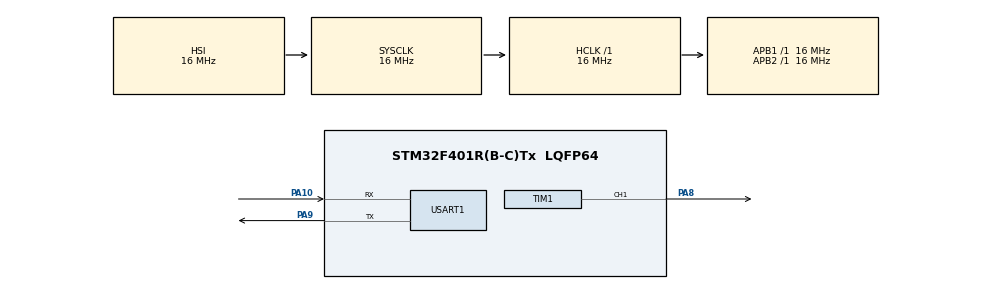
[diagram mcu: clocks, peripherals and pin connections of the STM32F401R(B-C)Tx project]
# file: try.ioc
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Mcu.Family=STM32F4
Mcu.Name=STM32F401R(B-C)Tx
Mcu.Package=LQFP64
NVIC.PriorityGroup=NVIC_PRIORITYGROUP_4
PA10.Mode=Asynchronous
PA10.Signal=USART1_RX
PA13.Mode=Serial_Wire
PA13.Signal=SYS_JTMS-SWDIO
PA14.Mode=Serial_Wire
PA14.Signal=SYS_JTCK-SWCLK
PA8.Signal=S_TIM1_CH1
PA9.Mode=Asynchronous
PA9.Signal=USART1_TX
PH0\ -\ OSC_IN.Mode=HSE-External-Oscillator
PH0\ -\ OSC_IN.Signal=RCC_OSC_IN
PH1\ -\ OSC_OUT.Mode=HSE-External-Oscillator
PH1\ -\ OSC_OUT.Signal=RCC_OSC_OUT
ProjectManager.HeapSize=0x200
ProjectManager.StackSize=0x400
ProjectManager.TargetToolchain=MDK-ARM V5.32
RCC.48MHZClocksFreq_Value=84000000
RCC.AHBFreq_Value=16000000
RCC.APB1Freq_Value=16000000
RCC.APB2Freq_Value=16000000
RCC.CortexFreq_Value=16000000
RCC.HSE_VALUE=8000000
RCC.HSI_VALUE=16000000
RCC.LSE_VALUE=32768
RCC.PLLM=4
RCC.PLLN=168
RCC.PLLP=RCC_PLLP_DIV4
RCC.PLLSourceVirtual=RCC_PLLSOURCE_HSE
RCC.SYSCLKFreq_VALUE=16000000
RCC.VCOOutputFreq_Value=336000000
SH.S_TIM1_CH1.0=TIM1_CH1,PWM Generation1 CH1
TIM1.Channel-PWM\ Generation1\ CH1=TIM_CHANNEL_1
TIM1.Period=4199
TIM1.Pulse-PWM\ Generation1\ CH1=2100
TIM2.AutoReloadPreload=TIM_AUTORELOAD_PRELOAD_ENABLE
TIM2.Period=9
TIM2.Prescaler=8399
USART1.VirtualMode=VM_ASYNC
VP_TIM1_VS_ClockSourceINT.Mode=Internal
VP_TIM2_VS_ClockSourceINT.Mode=Internal
board=custom

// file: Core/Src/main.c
/* USER CODE BEGIN Header */
/**
  ******************************************************************************
  * @file           : main.c
  * @brief          : Main program body
  ******************************************************************************
  * @attention
  *
  * Copyright (c) 2026 STMicroelectronics.
  * All rights reserved.
  *
  * This software is licensed under terms that can be found in the LICENSE file
  * in the root directory of this software component.
  * If no LICENSE file comes with this software, it is provided AS-IS.
  *
  ******************************************************************************
  */
/* USER CODE END Header */
#include "main.h"

/* USER CODE BEGIN Includes */
#include <stdio.h>   // for snprintf
#include <string.h>  // for strcmp / strncmp
#include <stdlib.h>  // for atoi
/* USER CODE END Includes */

TIM_HandleTypeDef htim1;
TIM_HandleTypeDef htim2;

UART_HandleTypeDef huart1;

/* USER CODE BEGIN PV */
uint32_t last_tick = 0;   // 上次发送的时间戳 (500ms)
uint32_t tx_count  = 0;   // 发送计数

uint8_t  rx_buf[64];      // 接收缓冲区
uint8_t  rx_idx   = 0;    // 已接收字节数
/* USER CODE END PV */

void SystemClock_Config(void);
static void MX_GPIO_Init(void);
static void MX_USART1_UART_Init(void);
static void MX_TIM1_Init(void);
static void MX_TIM2_Init(void);

int main(void)
{

  /* MCU Configuration--------------------------------------------------------*/

  /* Reset of all peripherals, Initializes the Flash interface and the Systick. */
  HAL_Init();

  /* Configure the system clock */
  SystemClock_Config();

  /* Initialize all configured peripherals */
  MX_GPIO_Init();
  MX_USART1_UART_Init();
  MX_TIM1_Init();
  MX_TIM2_Init();
  /* USER CODE BEGIN 2 */
  __HAL_RCC_GPIOA_CLK_ENABLE();

  GPIO_InitTypeDef GPIO_InitStruct = {0};
  GPIO_InitStruct.Pin  = GPIO_PIN_0;
  GPIO_InitStruct.Mode = GPIO_MODE_OUTPUT_PP;
  GPIO_InitStruct.Pull = GPIO_NOPULL;
  GPIO_InitStruct.Speed = GPIO_SPEED_FREQ_HIGH;
  HAL_GPIO_Init(GPIOA, &GPIO_InitStruct);

  // 启动提示
  const char *boot = "STM32F401 UART Ready\r\n";
  HAL_UART_Transmit(&huart1, (uint8_t *)boot, strlen(boot), 100);
  /* USER CODE END 2 */

  /* Infinite loop */
  while (1)
  {

      HAL_GPIO_WritePin(GPIOA, GPIO_PIN_0, GPIO_PIN_RESET); // ???
    /* USER CODE BEGIN 3 */
    // ====== ① 轮询接收串口字节 ======
    if (__HAL_UART_GET_FLAG(&huart1, UART_FLAG_RXNE))
    {
      uint8_t ch = (uint8_t)(huart1.Instance->DR & 0xFF);

      // 过滤换行/回车，但非空行时一并触发解析
      if (ch == '\n' || ch == '\r')
      {
        if (rx_idx == 0) continue;
        // 有缓冲数据 → 跳到处理
      }
      else if (rx_idx < sizeof(rx_buf) - 1)
      {
        rx_buf[rx_idx++] = ch;
      }

      // 收满6字节 或 遇到换行 → 立即解析
      if (rx_idx >= 6 || ch == '\n' || ch == '\r')
      {
        if (rx_idx == 6)
        {
          uint8_t dev_id = (rx_buf[0] - '0') * 10 + (rx_buf[1] - '0');
          uint8_t mode   = (rx_buf[2] - '0') * 10 + (rx_buf[3] - '0');
          uint8_t val    = (rx_buf[4] - '0') * 10 + (rx_buf[5] - '0');

          if (dev_id != 1)
          {
            // 回显收到的6个原始字节（含十六进制）
            char dbg[64];
            int n = snprintf(dbg, sizeof(dbg),
                "ERR:bad_id raw=%02X%02X%02X%02X%02X%02X\r\n",
                rx_buf[0], rx_buf[1], rx_buf[2], rx_buf[3], rx_buf[4], rx_buf[5]);
            HAL_UART_Transmit(&huart1, (uint8_t *)dbg, n, 100);
          }
          else if (mode == 0)
          {
            HAL_UART_Transmit(&huart1, (uint8_t *)"010002\r\n", 8, 100);
          }
          else if (mode == 1)
          {
            if (val > 100) val = 100;
            uint16_t pulse = (uint32_t)val * 4199 / 100;
            HAL_TIM_PWM_Start(&htim1, TIM_CHANNEL_1);
            __HAL_TIM_SET_COMPARE(&htim1, TIM_CHANNEL_1, pulse);

            char reply[32];
            int n = snprintf(reply, sizeof(reply),
                "OK PWM=%d%%\r\n", val);
            HAL_UART_Transmit(&huart1, (uint8_t *)reply, n, 100);
          }
          else
          {
            HAL_UART_Transmit(&huart1, (uint8_t *)"ERR:bad mode\r\n", 15, 100);
          }
        }
        else
        {
          // 长度不对 → 回显收到的数据
          char dbg[64];
          int n = snprintf(dbg, sizeof(dbg),
              "ERR:len=%d raw=", rx_idx);
          HAL_UART_Transmit(&huart1, (uint8_t *)dbg, n, 100);
          for (uint8_t i = 0; i < rx_idx; i++) {
            char hx[4];
            int hn = snprintf(hx, sizeof(hx), "%02X", rx_buf[i]);
            HAL_UART_Transmit(&huart1, (uint8_t *)hx, hn, 100);
          }
          HAL_UART_Transmit(&huart1, (uint8_t *)"\r\n", 2, 100);
        }
        rx_idx = 0;
      }
    }
  }
  /* USER CODE END 3 */
}

void SystemClock_Config(void)
{
  RCC_OscInitTypeDef RCC_OscInitStruct = {0};
  RCC_ClkInitTypeDef RCC_ClkInitStruct = {0};

  /** Configure the main internal regulator output voltage
  */
  __HAL_RCC_PWR_CLK_ENABLE();
  __HAL_PWR_VOLTAGESCALING_CONFIG(PWR_REGULATOR_VOLTAGE_SCALE2);

  /** Initializes the RCC Oscillators according to the specified parameters
  * in the RCC_OscInitTypeDef structure.
  */
  RCC_OscInitStruct.OscillatorType = RCC_OSCILLATORTYPE_HSI;
  RCC_OscInitStruct.HSIState = RCC_HSI_ON;
  RCC_OscInitStruct.HSICalibrationValue = RCC_HSICALIBRATION_DEFAULT;
  RCC_OscInitStruct.PLL.PLLState = RCC_PLL_NONE;
  if (HAL_RCC_OscConfig(&RCC_OscInitStruct) != HAL_OK)
  {
    Error_Handler();
  }

  /** Initializes the CPU, AHB and APB buses clocks
  */
  RCC_ClkInitStruct.ClockType = RCC_CLOCKTYPE_HCLK|RCC_CLOCKTYPE_SYSCLK
                              |RCC_CLOCKTYPE_PCLK1|RCC_CLOCKTYPE_PCLK2;
  RCC_ClkInitStruct.SYSCLKSource = RCC_SYSCLKSOURCE_HSI;
  RCC_ClkInitStruct.AHBCLKDivider = RCC_SYSCLK_DIV1;
  RCC_ClkInitStruct.APB1CLKDivider = RCC_HCLK_DIV1;
  RCC_ClkInitStruct.APB2CLKDivider = RCC_HCLK_DIV1;

  if (HAL_RCC_ClockConfig(&RCC_ClkInitStruct, FLASH_LATENCY_0) != HAL_OK)
  {
    Error_Handler();
  }
}

static void MX_TIM1_Init(void)
{

  TIM_ClockConfigTypeDef sClockSourceConfig = {0};
  TIM_MasterConfigTypeDef sMasterConfig = {0};
  TIM_OC_InitTypeDef sConfigOC = {0};
  TIM_BreakDeadTimeConfigTypeDef sBreakDeadTimeConfig = {0};

  htim1.Instance = TIM1;
  htim1.Init.Prescaler = 0;
  htim1.Init.CounterMode = TIM_COUNTERMODE_UP;
  htim1.Init.Period = 4199;
  htim1.Init.ClockDivision = TIM_CLOCKDIVISION_DIV1;
  htim1.Init.RepetitionCounter = 0;
  htim1.Init.AutoReloadPreload = TIM_AUTORELOAD_PRELOAD_DISABLE;
  if (HAL_TIM_Base_Init(&htim1) != HAL_OK)
  {
    Error_Handler();
  }
  sClockSourceConfig.ClockSource = TIM_CLOCKSOURCE_INTERNAL;
  if (HAL_TIM_ConfigClockSource(&htim1, &sClockSourceConfig) != HAL_OK)
  {
    Error_Handler();
  }
  if (HAL_TIM_PWM_Init(&htim1) != HAL_OK)
  {
    Error_Handler();
  }
  sMasterConfig.MasterOutputTrigger = TIM_TRGO_RESET;
  sMasterConfig.MasterSlaveMode = TIM_MASTERSLAVEMODE_DISABLE;
  if (HAL_TIMEx_MasterConfigSynchronization(&htim1, &sMasterConfig) != HAL_OK)
  {
    Error_Handler();
  }
  sConfigOC.OCMode = TIM_OCMODE_PWM1;
  sConfigOC.Pulse = 2100;
  sConfigOC.OCPolarity = TIM_OCPOLARITY_HIGH;
  sConfigOC.OCNPolarity = TIM_OCNPOLARITY_HIGH;
  sConfigOC.OCFastMode = TIM_OCFAST_DISABLE;
  sConfigOC.OCIdleState = TIM_OCIDLESTATE_RESET;
  sConfigOC.OCNIdleState = TIM_OCNIDLESTATE_RESET;
  if (HAL_TIM_PWM_ConfigChannel(&htim1, &sConfigOC, TIM_CHANNEL_1) != HAL_OK)
  {
    Error_Handler();
  }
  sBreakDeadTimeConfig.OffStateRunMode = TIM_OSSR_DISABLE;
  sBreakDeadTimeConfig.OffStateIDLEMode = TIM_OSSI_DISABLE;
  sBreakDeadTimeConfig.LockLevel = TIM_LOCKLEVEL_OFF;
  sBreakDeadTimeConfig.DeadTime = 0;
  sBreakDeadTimeConfig.BreakState = TIM_BREAK_DISABLE;
  sBreakDeadTimeConfig.BreakPolarity = TIM_BREAKPOLARITY_HIGH;
  sBreakDeadTimeConfig.AutomaticOutput = TIM_AUTOMATICOUTPUT_DISABLE;
  if (HAL_TIMEx_ConfigBreakDeadTime(&htim1, &sBreakDeadTimeConfig) != HAL_OK)
  {
    Error_Handler();
  }
  HAL_TIM_MspPostInit(&htim1);

}

static void MX_TIM2_Init(void)
{

  TIM_ClockConfigTypeDef sClockSourceConfig = {0};
  TIM_MasterConfigTypeDef sMasterConfig = {0};

  htim2.Instance = TIM2;
  htim2.Init.Prescaler = 8399;
  htim2.Init.CounterMode = TIM_COUNTERMODE_UP;
  htim2.Init.Period = 9;
  htim2.Init.ClockDivision = TIM_CLOCKDIVISION_DIV1;
  htim2.Init.AutoReloadPreload = TIM_AUTORELOAD_PRELOAD_ENABLE;
  if (HAL_TIM_Base_Init(&htim2) != HAL_OK)
  {
    Error_Handler();
  }
  sClockSourceConfig.ClockSource = TIM_CLOCKSOURCE_INTERNAL;
  if (HAL_TIM_ConfigClockSource(&htim2, &sClockSourceConfig) != HAL_OK)
  {
    Error_Handler();
  }
  sMasterConfig.MasterOutputTrigger = TIM_TRGO_RESET;
  sMasterConfig.MasterSlaveMode = TIM_MASTERSLAVEMODE_DISABLE;
  if (HAL_TIMEx_MasterConfigSynchronization(&htim2, &sMasterConfig) != HAL_OK)
  {
    Error_Handler();
  }

}

static void MX_USART1_UART_Init(void)
{

  huart1.Instance = USART1;
  huart1.Init.BaudRate = 115200;
  huart1.Init.WordLength = UART_WORDLENGTH_8B;
  huart1.Init.StopBits = UART_STOPBITS_1;
  huart1.Init.Parity = UART_PARITY_NONE;
  huart1.Init.Mode = UART_MODE_TX_RX;
  huart1.Init.HwFlowCtl = UART_HWCONTROL_NONE;
  huart1.Init.OverSampling = UART_OVERSAMPLING_16;
  if (HAL_UART_Init(&huart1) != HAL_OK)
  {
    Error_Handler();
  }

}

static void MX_GPIO_Init(void)
{

  /* GPIO Ports Clock Enable */
  __HAL_RCC_GPIOH_CLK_ENABLE();
  __HAL_RCC_GPIOA_CLK_ENABLE();

}

void Error_Handler(void)
{
  __disable_irq();
  while (1)
  {
  }
}
